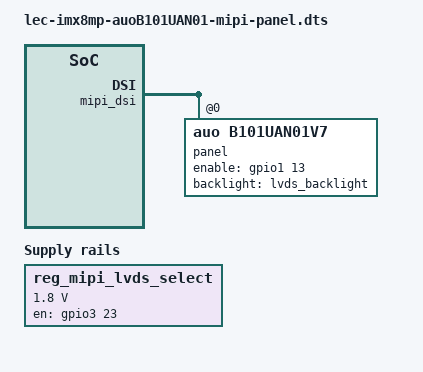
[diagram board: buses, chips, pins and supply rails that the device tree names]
/*
 * Copyright 2020 NXP
 */

#include "lec-imx8mp.dts"

/ {
	lvds_backlight {
		enable-gpios = <&gpio1 10 GPIO_ACTIVE_HIGH>;
	};

	// gpio3_IO23 on lec-imx8mp is display mux
	reg_mipi_lvds_select: regulator-mipi-lvds {
		compatible = "regulator-fixed";
		regulator-name = "mipi_lvds_select_vbus";
		pinctrl-names = "default";
		pinctrl-0 = <&pinctrl_disp_select>;
		regulator-min-microvolt = <1800000>;
		regulator-max-microvolt = <1800000>;
		gpio = <&gpio3 23 GPIO_ACTIVE_HIGH>;
		enable-active-high;
		regulator-always-on;
	};
};

&mipi_dsi {
	status = "okay";
	panel@0 {
		compatible = "auo,b101uan01v7";
		reg = <0>;
		pinctrl-0 = <&pinctrl_lvds_pwr_en>;
		enable-gpios = <&gpio1 13 GPIO_ACTIVE_HIGH>;
		status = "okay";

		dsi-lanes = <4>;
		video-mode = <0>;
		panel-width-mm = <293>;
		panel-height-mm = <165>;
		backlight = <&lvds_backlight>;

		display-timings {
			timing {
				clock-frequency = <148000000>;
				hactive = <1920>;
				vactive = <1200>;
				hfront-porch = <77>;
				hsync-len = <56>;
				hback-porch = <117>;
				vfront-porch = <11>;
				vsync-len = <19>;
				vback-porch = <19>;
				hsync-active = <0>;
				vsync-active = <0>;
				de-active = <0>;
				pixelclk-active = <0>;
			};
		};
	};
};
